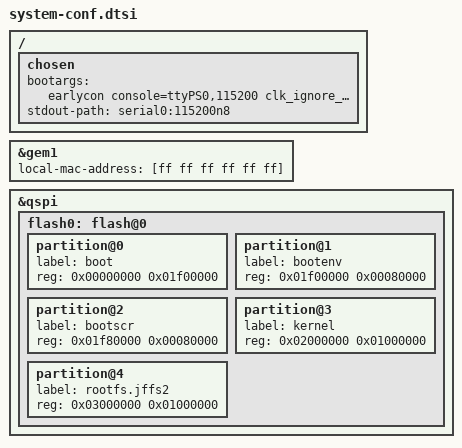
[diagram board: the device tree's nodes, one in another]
/*
 * CAUTION: This file is automatically generated by PetaLinux SDK.
 * DO NOT modify this file
 */


/ {
	chosen {
		bootargs = " earlycon console=ttyPS0,115200 clk_ignore_unused root=/dev/mmcblk1p2 rw rootwait";
		stdout-path = "serial0:115200n8";
	};
};

&gem1 {
	local-mac-address = [ff ff ff ff ff ff];
};

&qspi {
	#address-cells = <1>;
	#size-cells = <0>;
	flash0: flash@0 {
		/delete-node/ partition@0;
		/delete-node/ partition@100000;
		/delete-node/ partition@600000;
		/delete-node/ partition@620000;
		/delete-node/ partition@c00000;
		partition@0 {
			label = "boot";
			reg = <0x00000000 0x01f00000>;
		};
		partition@1 {
			label = "bootenv";
			reg = <0x01f00000 0x00080000>;
		};
		partition@2 {
			label = "bootscr";
			reg = <0x01f80000 0x00080000>;
		};
		partition@3 {
			label = "kernel";
			reg = <0x02000000 0x01000000>;
		};
		partition@4 {
			label = "rootfs.jffs2";
			reg = <0x03000000 0x01000000>;
		};
	};
};

